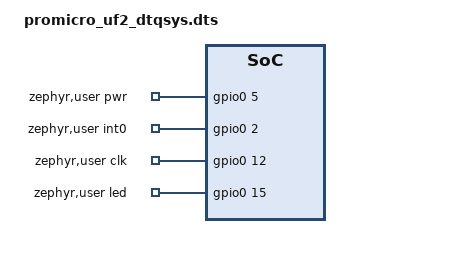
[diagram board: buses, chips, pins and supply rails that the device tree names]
// DTQSYS nRF52840 / ICM45686 (SPI) / QMC6309 (I2C)
// Hardware pin assignments taken from DTQSYS manufacturer promicro_uf2.dts.
// Keep inherited modern Zephyr user properties and firmware code.
/dts-v1/;
#include "promicro_uf2.dts"

&spi3_default {
    group1 {
        psels = <NRF_PSEL(SPIM_MISO, 1, 9)>,
                <NRF_PSEL(SPIM_MOSI, 1, 8)>,
                <NRF_PSEL(SPIM_SCK, 0, 7)>;
    };
};

&spi3_sleep {
    group1 {
        psels = <NRF_PSEL(SPIM_MISO, 1, 9)>,
                <NRF_PSEL(SPIM_MOSI, 1, 8)>,
                <NRF_PSEL(SPIM_SCK, 0, 7)>;
    };
};

/ {
    zephyr,user {
        pwr-gpios = <&gpio0 5 GPIO_OPEN_SOURCE>;
        int0-gpios = <&gpio0 2 6>; // Manufacturer uses raw GPIO flags 6; verify on hardware
        clk-gpios = <&gpio0 12 GPIO_OPEN_DRAIN>;
        led-gpios = <&gpio0 15 GPIO_OPEN_SOURCE>;
    };
};

&spi3 {
    cs-gpios = <&gpio0 4 GPIO_ACTIVE_LOW>;
};
